# cyt4dn register map
Vendor: Cypress Semiconductor; Series: cyt4dn; File version: 1.0
CPU: CM7 r0p1, little endian, MPU, FPU, VTOR, 3 interrupt priority bits
Registers are 32-bit, read-write, reset 0x0 unless marked. A register's access mark holds for its fields unless they carry their own. Offsets are from the block's base; [hi:lo] are bit positions; lines under a group give offsets from that group; {n}, {i} and the like mark numbered series; 'fields as' and 'values as' point back to an identical list.

## VIDEOSS0 (part 13 of 18) — Video and Graphics Subsystem IP
Base 0x40A00000
0x80000 VIDEOIO group — Video I/O Core
  0x24000 DISENG1 group — Display Engine
    0x1000 SIG1 group — Signature Unit
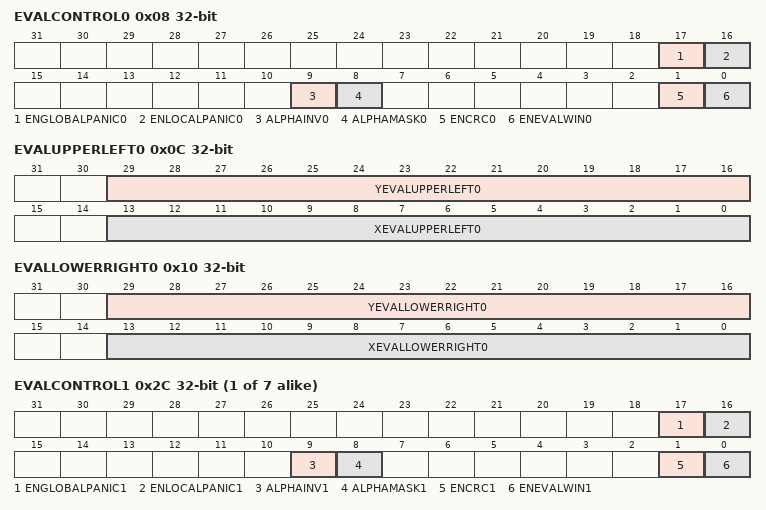
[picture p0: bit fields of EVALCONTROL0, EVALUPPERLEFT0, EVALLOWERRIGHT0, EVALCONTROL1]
      0x08 EVALCONTROL0 — Control settings for evaluation window 0.
        [17] ENGLOBALPANIC0 — When enabled (value 1) the error status of this window (StsSigError) will activate the panic mode of the display stream's Frame Generator, which can switch to another display mode in response.
        [16] ENLOCALPANIC0 — When enabled (value 1) the error status this window (StsSigError) will replace all pixels inside the window by a constant color on the display. Skip regions due to other evaluation windows on top are not modified. AlphaMask, when enabled, is not considered for this replacement.
        [9] ALPHAINV0 — When enabled (value 1) the effect of AlphaMask is inverted (pixels with alpha bit = 1 are ignored then).
        [8] ALPHAMASK0 — When enabled (value 1) pixels with alpha bit = 0 are ignored for signature computation.
        [1] ENCRC0 — When enabled (value 1) the measured signature is checked against a reference value (SigCRCRef).
        [0] ENEVALWIN0 — When enabled (value 1) a CRC signature is computed for all pixels inside this evaluation window (SigCRC). When this bit is cleared, the internal status for this window is reset (StsSigError bit and frame counters).
      0x0C EVALUPPERLEFT0 — Upper left corner of evaluation window 0.
        [29:16] YEVALUPPERLEFT0 — Y coordinate.
        [13:0] XEVALUPPERLEFT0 — X coordinate.
      0x10 EVALLOWERRIGHT0 — Lower right corner of evaluation window 0.
        [29:16] YEVALLOWERRIGHT0 — Y coordinate.
        [13:0] XEVALLOWERRIGHT0 — X coordinate.
      0x14 SIGCRCREDREF0 reset 0xFFFFFFFF — Reference signature of red channel for evaluation window 0.
        [31:0] SIGCRCREDREF0 — Reference value that is compared against measured SigCRCRed value.
      0x18 SIGCRCGREENREF0 reset 0xFFFFFFFF — Reference signature of green channel for evaluation window 0.
        [31:0] SIGCRCGREENREF0 — Reference value that is compared against measured SigCRCGreen value.
      0x1C SIGCRCBLUEREF0 reset 0xFFFFFFFF — Reference signature of blue channel for evaluation window 0.
        [31:0] SIGCRCBLUEREF0 — Reference value that is compared against measured SigCRCBlue value.
      0x20 SIGCRCRED0 ro reset 0xFFFFFFFF — Measured signature of red channel for evaluation window 0.
        [31:0] SIGCRCRED0 — CRC values from red channel.
      0x24 SIGCRCGREEN0 ro reset 0xFFFFFFFF — Measured signature of green channel for evaluation window 0.
        [31:0] SIGCRCGREEN0 — CRC values from green channel.
      0x28 SIGCRCBLUE0 ro reset 0xFFFFFFFF — Measured signature of blue channel for evaluation window 0.
        [31:0] SIGCRCBLUE0 — CRC values from blue channel.
      {0x8+0x24*l} EVALCONTROL{l} (l=1..7) — Control settings for evaluation window {l}.
        [17] ENGLOBALPANIC{l} — See EnGlobalPanic0.
        [16] ENLOCALPANIC{l} — See EnLocalPanic0.
        [9] ALPHAINV{l} — See AlphaInv0.
        [8] ALPHAMASK{l} — See AlphaMask0.
        [1] ENCRC{l} — See EnCRC0.
        [0] ENEVALWIN{l} — See EnEvalWin0.
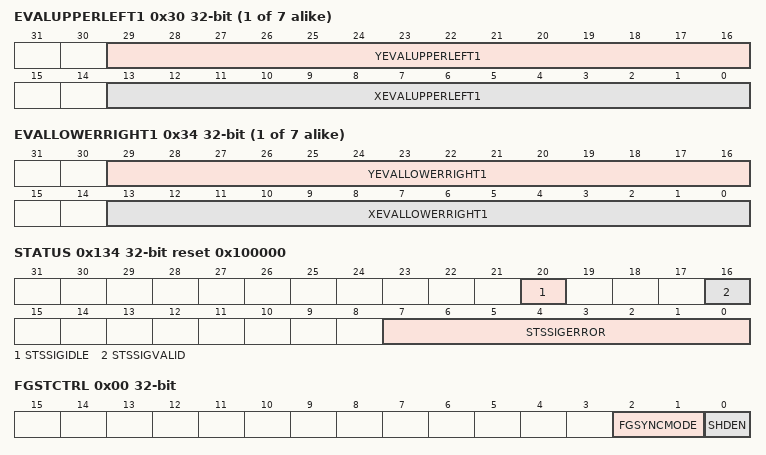
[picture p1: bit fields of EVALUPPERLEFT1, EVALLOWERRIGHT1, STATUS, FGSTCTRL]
      {0xC+0x24*l} EVALUPPERLEFT{l} (l=1..7) — Upper left corner of evaluation window {l}.
        [29:16] YEVALUPPERLEFT{l} — See YEvalUpperLeft0.
        [13:0] XEVALUPPERLEFT{l} — See XEvalUpperLeft0.
      {0x10+0x24*l} EVALLOWERRIGHT{l} (l=1..7) — Lower right corner of evaluation window {l}.
        [29:16] YEVALLOWERRIGHT{l} — See YEvalLowerRight0.
        [13:0] XEVALLOWERRIGHT{l} — See XEvalLowerRight0.
      {0x14+0x24*l} SIGCRCREDREF{l} reset 0xFFFFFFFF (l=1..7) — Reference signature of red channel for evaluation window {l}.
        [31:0] SIGCRCREDREF{l} — See SigCRCRedRef0.
      {0x18+0x24*l} SIGCRCGREENREF{l} reset 0xFFFFFFFF (l=1..7) — Reference signature of green channel for evaluation window {l}.
        [31:0] SIGCRCGREENREF{l} — See SigCRCGreenRef0.
      {0x1C+0x24*l} SIGCRCBLUEREF{l} reset 0xFFFFFFFF (l=1..7) — Reference signature of blue channel for evaluation window {l}.
        [31:0] SIGCRCBLUEREF{l} — See SigCRCBlueRef0.
      {0x20+0x24*l} SIGCRCRED{l} ro reset 0xFFFFFFFF (l=1..7) — Measured signature of red channel for evaluation window {l}.
        [31:0] SIGCRCRED{l} — See SigCRCRed0.
      {0x24+0x24*l} SIGCRCGREEN{l} ro reset 0xFFFFFFFF (l=1..7) — Measured signature of green channel for evaluation window {l}.
        [31:0] SIGCRCGREEN{l} — See SigCRCGreen0.
      {0x28+0x24*l} SIGCRCBLUE{l} ro reset 0xFFFFFFFF (l=1..7) — Measured signature of blue channel for evaluation window {l}.
        [31:0] SIGCRCBLUE{l} — See SigCRCBlue0.
      0x128 SHADOWLOAD — Shadow load control register.
        [7:0] SHDLDREQ — Shadow load request for each evaluation window (bit index = window index). Writing a '1' to a bit will load the shadows into the active configuration for that window at start of next frame. Writing a '0' has no effect. The flag is reset by HW once the shadows have been loaded. A shadow load interrupt signal is generated when shadows have been loaded for at least one evaluation window. Has only effect when ShdLdSel is set to LOCAL.
      0x12C CONTINUOUSMODE — Signature operation mode control.
        [0] ENCONT — EnCont = 0: disables continuous mode. Signatures will be generated only once and in idle state after completion of measurement. In this 'ONE_TIME' mode the signature must be triggered by 'Kick' field. EnCont = 1: enables continuous mode. Write '1' to this field, signature starts and measures every incoming frame until EnCont is turned to 0. 'Kick' has no effect when 'EnCont' = 1.
      0x130 SOFTWAREKICK wo reset not defined — Signature measurement trigger.
        [0] KICK — ContinueMode.EnCont=0: Write '1' to this field in order to start signature computation with next frame. ContinueMode.EnCont=1: This field is ignored.
      0x134 STATUS ro reset 0x100000 — Module status.
        [20] STSSIGIDLE — StsSigIdle = 1: Signature is in Idle state. StsSigIdle = 0: Signature runs.
        [16] STSSIGVALID — Measured signature values are valid. This flag is set when the SigCRC fields have been updated for all enabled evaluation windows. In that case also the corresponding interrupt event is triggered. It is reset when SW writes a '1' to the 'Kick' field in order to start a new measurement.
        [7:0] STSSIGERROR — Error status bits for all evaluation windows (bit index = window index). When a bit is set it means that measured signature value is different from reference value (SigCRCRef). The bit is set when EnCRC is active and a certain number of frames have a violation (ErrThres). It is reset when the reference check for evaluation window is disabled (EnEvalWin or EnCRC) or in case a certain number of consecutive frames have no violation (ErrThresReset). The value corresponds to the panic status of this evaluation window.
    0x2000 FRAMEGEN1 group — Frame Generator
      0x00 FGSTCTRL — FrameGen Static Control Register
        [2:1] FGSYNCMODE — Determines the operating mode of the framegen unit for side-by-side synchronization. The framegen unit programmed as master generates synchronization pulses. The framegen units programmed as slaves are synchronized to the master unit. There must be only one framegen unit programmed acting as master.
          0=OFF (No side-by-side synchronization.); 1=MASTER (Framegen is master.); 2=SLAVE_CYC (Framegen is slave. Runs in cyclic synchronization mode.); 3=SLAVE_ONCE (Framegen is slave. Runs in one time synchronization mode.)
        [0] SHDEN — Enables shadowing for RWS type configuration fields. Otherwise shadow registers are immediately updated when written.
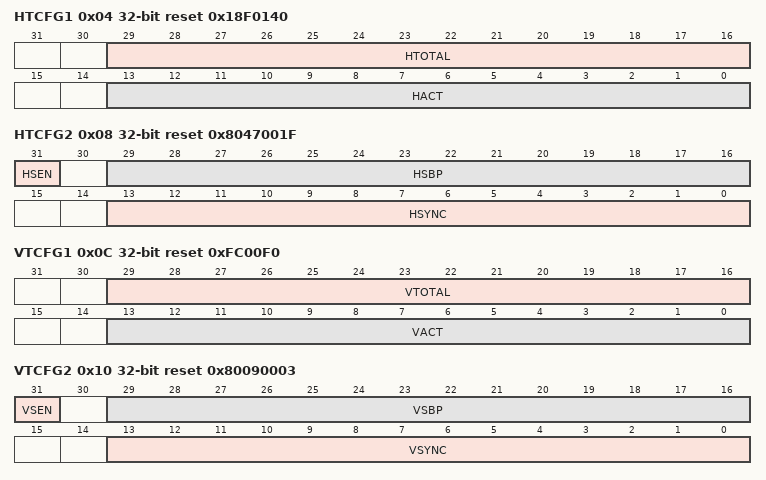
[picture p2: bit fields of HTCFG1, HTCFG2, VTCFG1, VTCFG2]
      0x04 HTCFG1 reset 0x18F0140 — FrameGen Horizontal Timing Config Register 1
        [29:16] HTOTAL — Total horizontal size of frame in pixels. (Set value +1 is the total horizontal size of frame) Htotal shall be greater or equal than Hact + Hsbp. Note1: Valid setup for horizontal video timing contains parameters Hact, Htotal, Hsbp and, if enabled, Hsync. Note2: If SRAdj==1 then Htotal[0] shall be equal the value of SREven (for sec. channel only).
        [13:0] HACT — Horizontal size of active display area in pixels. Hact shall be greater or equal than 4. Note: Valid setup for horizontal video timing contains parameters Hact, Htotal, Hsbp and, if enabled, Hsync.
      0x08 HTCFG2 reset 0x8047001F — FrameGen Horizontal Timing Config Register 2
        [31] HSEN — Enables generation of HSYNC pulse.
        [29:16] HSBP — Width of HSYNC pulse plus width of horizontal back porch in pixels. (Set value +1 is the width of HSYNC pulse plus width of horizontal back porch) Hsbp shall be greater or equal than Hsync. Note: Valid setup for horizontal video timing contains parameters Hact, Htotal, Hsbp and, if enabled, Hsync.
        [13:0] HSYNC — Width of HSYNC pulse in pixels. (Set value +1 is the width of HSYNC pulse) HSYNC is of zero width if HsEn==0. Note: Valid setup for horizontal video timing contains parameters Hact, Htotal, Hsbp and, if enabled, Hsync.
      0x0C VTCFG1 reset 0xFC00F0 — FrameGen Vertical Timing Config Register 1
        [29:16] VTOTAL — Total vertical size of frame in lines. (Set value +1 is the total vertical size of frame) Vtotal shall be greater or equal than Vact + Vsbp. Note: Valid setup for vertical video timing contains parameters Vact, Vtotal, Vsbp and, if enabled, Vsync.
        [13:0] VACT — Vertical size of active display area in lines. Vact shall be greater or equal than 4. Note: Valid setup for vertical video timing contains parameters Vact, Vtotal, Vsbp and, if enabled, Vsync.
      0x10 VTCFG2 reset 0x80090003 — FrameGen Vertical Timing Config Register 2
        [31] VSEN — Enables generation of VSYNC pulse.
        [29:16] VSBP — Width of VSYNC pulse plus width of vertical back porch in lines. (Set value +1 is the width of VSYNC pulse plus width of vertical back porch) Vsbp shall be greater or equal than Vsync. Note: Valid setup for vertical video timing contains parameters Vact, Vtotal, Vsbp and, if enabled, Vsync.
        [13:0] VSYNC — Width of VSYNC pulse in lines. (Set value +1 is the width of VSYNC pulse) VSYNC is of zero width if VsEn==0. Note: Valid setup for vertical video timing contains parameters Vact, Vtotal, Vsbp and, if enabled, Vsync.
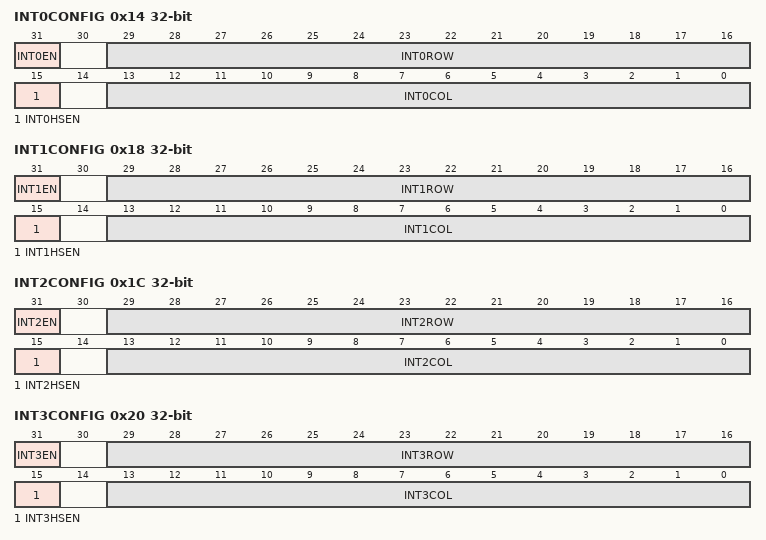
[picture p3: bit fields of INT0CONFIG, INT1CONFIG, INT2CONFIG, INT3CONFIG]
      0x14 INT0CONFIG — Coordinates of the trigger point for generation of the Int0 interrupt signal
        [31] INT0EN — Enables Int0.
        [29:16] INT0ROW — Specifies on which row of the display raster the Int0 signal is triggered (1 .. Int0Row .. VTOTAL). Adaptive display timing must be taken into account when defining Int0Row (1 .. Int0Row .. VTOTAL_MIN).
        [15] INT0HSEN — When enabled, Int0Row setting is ignored so that the interrupt occurs every line at position given by Int0Col.
        [13:0] INT0COL — Specifies on which column of the display raster the Int0 signal is triggered (1 .. Int0Col .. HTOTAL). Adaptive display timing must be taken into account when defining Int0Col (1 .. Int0Col .. HTOTAL_MIN).
      0x18 INT1CONFIG — Coordinates of the trigger point for generation of the Int1 interrupt signal
        [31] INT1EN — Enables Int1 (irq[1]).
        [29:16] INT1ROW — Specifies on which row of the display raster the Int1 signal is triggered (1 .. Int1Row .. VTOTAL). Adaptive display timing must be taken into account when defining Int1Row (1 .. Int1Row .. VTOTAL_MIN).
        [15] INT1HSEN — When enabled, Int1Row setting is ignored so that the interrupt occurs every line at position given by Int1Col.
        [13:0] INT1COL — Specifies on which column of the display raster the Int1 signal is triggered (1 .. Int1Col .. HTOTAL). Adaptive display timing must be taken into account when defining Int1Col (1 .. Int1Col .. HTOTAL_MIN).
      0x1C INT2CONFIG — Coordinates of the trigger point for generation of the Int2 interrupt signal
        [31] INT2EN — Enables Int2.
        [29:16] INT2ROW — Specifies on which row of the display raster the Int2 signal is triggered (1 .. Int2Row .. VTOTAL). Adaptive display timing must be taken into account when defining Int2Row (1 .. Int2Row .. VTOTAL_MIN).
        [15] INT2HSEN — When enabled, Int2Row setting is ignored so that the interrupt occurs every line at position given by Int2Col.
        [13:0] INT2COL — Specifies on which column of the display raster the Int2 signal is triggered (1 .. Int2Col .. HTOTAL). Adaptive display timing must be taken into account when defining Int2Col (1 .. Int2Col .. HTOTAL_MIN).
      0x20 INT3CONFIG — Coordinates of the trigger point for generation of the Int3 interrupt signal
        [31] INT3EN — Enables Int3.
        [29:16] INT3ROW — Specifies on which row of the display raster the Int3 signal is triggered (1 .. Int3Row .. VTOTAL). Adaptive display timing must be taken into account when defining Int3Row (1 .. Int3Row .. VTOTAL_MIN).
        [15] INT3HSEN — When enabled, Int3Row setting is ignored so that the interrupt occurs every line at position given by Int3Col.
        [13:0] INT3COL — Specifies on which column of the display raster the Int3 signal is triggered (1 .. Int3Col .. HTOTAL). Adaptive display timing must be taken into account when defining Int3Col (1 .. Int3Col .. HTOTAL_MIN).
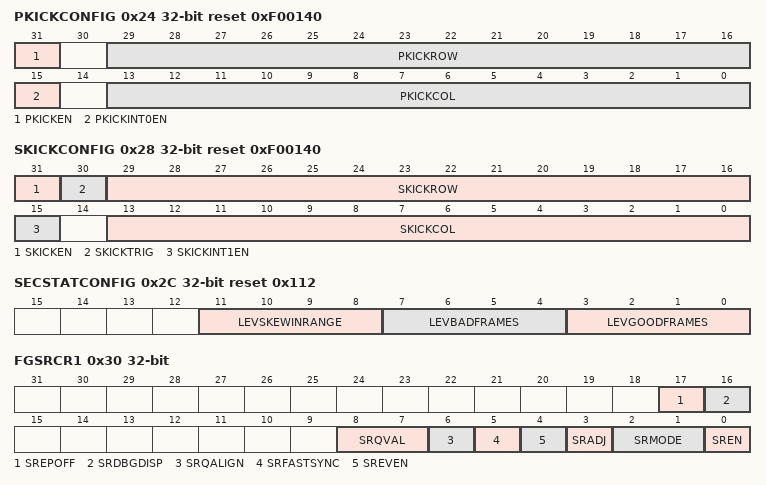
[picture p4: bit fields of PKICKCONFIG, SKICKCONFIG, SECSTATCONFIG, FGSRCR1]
      0x24 PKICKCONFIG reset 0xF00140 — Coordinates of the trigger point for generation of the primary kick signal
        [31] PKICKEN — Enables pkick signal.
        [29:16] PKICKROW — Specifies on which row of the display raster the pkick signal is triggered (1 .. PKickRow .. VTOTAL). Adaptive display timing must be taken into account when defining PKickRow (1 .. PKickRow .. VTOTAL_MIN).
        [15] PKICKINT0EN — If enabled, maps the primary kick signal (pkick) on the interrupt pin int0. Overrides int0en.
        [13:0] PKICKCOL — Specifies on which column of the display raster the pkick signal is triggered (1 .. PKickCol .. HTOTAL). Adaptive display timing must be taken into account when defining PKickCol (1 .. PKickCol .. HTOTAL_MIN).
      0x28 SKICKCONFIG reset 0xF00140 — Coordinates of the trigger point for generation of the secondary kick signal
        [31] SKICKEN — Enables generation of internal skick signal.
        [30] SKICKTRIG — Select source for skick generation.
          0=INTERNAL (Use internal skick signal, trigger point defined by SKickRow and SKickCol.); 1=EXTERNAL (Use external skick input as trigger.)
        [29:16] SKICKROW — Specifies on which row of the display raster the skick signal is triggered (1 .. SKickRow .. VTOTAL). Adaptive display timing must be taken into account when defining SKickRow (1 .. SKickRow .. VTOTAL_MIN).
        [15] SKICKINT1EN — If enabled, maps the secondary kick signal (skick) on the interrupt pin int1. Overrides int1en.
        [13:0] SKICKCOL — Specifies on which column of the display raster the skick signal is triggered (1 .. SKickCol .. HTOTAL). Adaptive display timing must be taken into account when defining SKickCol (1 .. SKickCol .. HTOTAL_MIN).
      0x2C SECSTATCONFIG reset 0x112 — Configuration register for controlling the behavior of the SecSyncStat field in the FgSecChStat register.
        [11:8] LEVSKEWINRANGE — Number of continuous frames the measured skew value shall be within the range defined by SyncRangeLow and SyncRangeHigh. If this condition is true, additionally LevGoodFrames valid frames must be processed before the status line of the sec. channel and the SecSyncStat status field goes to 1 indicating synchronized status. Value of 0 is not allowed.
        [7:4] LEVBADFRAMES — Not used.
        [3:0] LEVGOODFRAMES — Number of continuous correct frames that must be processed before SecSyncStat field goes 1 (in sync). Value of 0 is not allowed.
      0x30 FGSRCR1 — FrameGen Skew Regulation Control Register 1.
        [17] SREPOFF — Disables the skew Extrapolation in blanking.
        [16] SRDBGDISP — If enabled, the pixels are displayed that are read from FIFO when secondary channel is not in sync yet. Otherwise constant color is displayed in unsynchronized state.
        [8:7] SRQVAL — If SRQAlign is enabled, this field determines the fixed value of the two LSB bits of HTOTAL. Note: This has impact on the settings for Htotal, HtotalMin and HtotalMax.
          0=ZERO (Fixed two LSB values of HTOTAL are 0b00.); 1=ONE (Fixed two LSB values of HTOTAL are 0b01.); 2=TWO (Fixed two LSB values of HTOTAL are 0b10.); 3=THREE (Fixed two LSB values of HTOTAL are 0b11.)
        [6] SRQALIGN — Enables alignment of HTOTAL to be a multiple of 4. Overrides SREven field. Program field SRQVal for the desired value of the two LSB bits of HTOTAL.
        [5] SRFASTSYNC — Fast Synchronization Mode. Frame Generator is started synchronized to frame timing on secondary channel when switching FgEn from 0 to 1. This allows fast locking of skew regulation.
        [4] SREVEN — Total line length HTOTAL is even when SRAdj is enabled. Note: This has impact on the settings for Htotal, HtotalMin and HtotalMax.
        [3] SRADJ — Enables line length adjustment for HTOTAL. If SRQAlign=0, SREven determines whether HTOTAL has odd (SREven=0) or even (SrEven=1) number of pixels. If SRQAlign=1, SRQVal determines the value of the two LSB bits of HTOTAL.
        [2:1] SRMODE — Skew Control Operating Mode.
          0=OFF (Skew Regulation is off.); 1=HREG (Horizontal regulation enabled.); 2=VREG (Vertical regulation enabled.); 3=BOTH (Both regulation modes are enabled.)
        [0] SREN — If enabled, skew control for secondary channel is active. If disabled, skew control for secondary channel is in fetch mode. Fetch mode: secondary channel fetches frames and can intentionally produce a backstall via setting sbusy signal to active. This mode is intended to fetch frames from memory via a stallable pipeline, like the primary interface. No timing adaption of frames takes place in this mode.
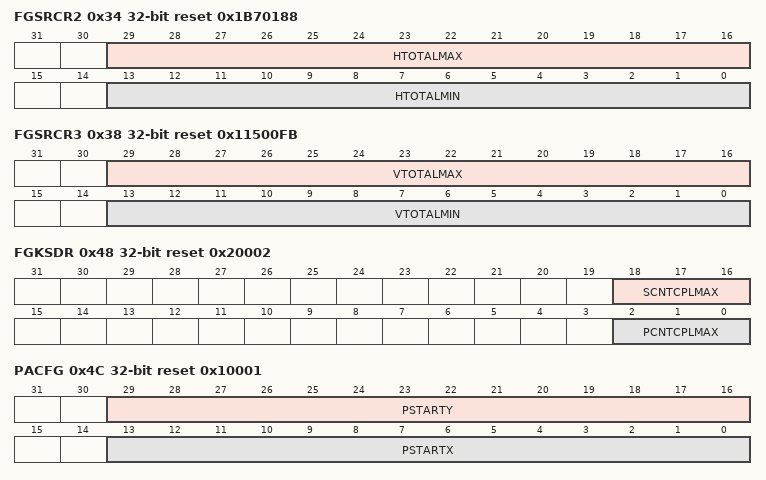
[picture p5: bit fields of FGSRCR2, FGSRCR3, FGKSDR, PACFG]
      0x34 FGSRCR2 reset 0x1B70188 — FrameGen Skew Regulation Control Register 2
        [29:16] HTOTALMAX — Maximum value of htotal when horizontal regulation is enabled. (Set value +1 is the maximum value of htotal) HTotalMax must be greater or equal Htotal. Note: If SRAdj==1 then HtotalMax[0] shall be equal to the value of SREven.
        [13:0] HTOTALMIN — Minimum value of htotal when horizontal regulation is enabled. (Set value +1 is the minimum value of htotal, must be greater or equal Hsbp + Hactive) HTotalMin must be smaller or equal Htotal. Note: If SRAdj==1 then HtotalMin[0] shall be equal to the value of SREven.
      0x38 FGSRCR3 reset 0x11500FB — FrameGen Skew Regulation Control Register 3
        [29:16] VTOTALMAX — Maximum value of vtotal when vertical regulation is enabled. (Set value +1 is the maximum value of vtotal)
        [13:0] VTOTALMIN — Minimum value of vtotal when vertical regulation is enabled. (Set value +1 is the minimum value of vtotal, must be greater or equal Vsbp + Vactive + 1)
      0x3C FGSRCR4 reset 0xC8 — FrameGen Skew Regulation Control Register 4
        [28:0] TARGETSKEW — Horizontal target skew value for horizontal and vertical skew regulation (signed value). (format is signed integer)
      0x40 FGSRCR5 — FrameGen Skew Regulation Control Register 5
        [28:0] SYNCRANGELOW — Sync range of horizontal and vertical skew regulation. Lower value (signed value). If skew stays within programmed sync range, frame status is assumed synchronized. (format is signed integer)
      0x44 FGSRCR6 reset 0x190 — FrameGen Skew Regulation Control Register 6
        [28:0] SYNCRANGEHIGH — Sync range of horizontal and vertical skew regulation. Upper value (signed value). If skew stays within programmed sync range, frame status is assumed synchronized. (format is signed integer)
      0x48 FGKSDR reset 0x20002 — FrameGen Kick System Debug Register
        [18:16] SCNTCPLMAX — Maximum Value for spendcnt_cpl_s complementary secondary kick counter. Do not change!
        [2:0] PCNTCPLMAX — Maximum Value for ppendcnt_cpl_s complementary primary kick counter. Do not change!
      0x4C PACFG reset 0x10001 — FrameGen Primary Area Config Register 1 (shadowed)
        [29:16] PSTARTY — Primary screen upper left corner, y component. Counts from 1. Pstarty = 0 is not allowed. Primary screen shall not overlap the last column/ last row of the total frame defined by Htotal/ Vtotal.
        [13:0] PSTARTX — Primary screen upper left corner, x component. Counts from 1. Pstartx = 0 is not allowed. Primary screen shall not overlap the last column/ last row of the total frame defined by Htotal/ Vtotal.
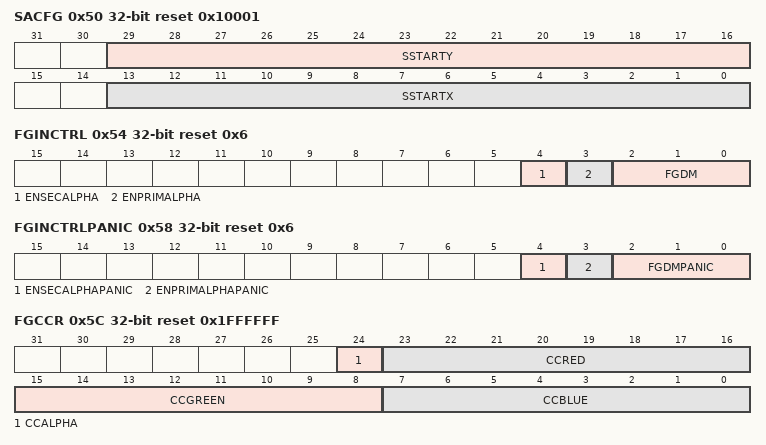
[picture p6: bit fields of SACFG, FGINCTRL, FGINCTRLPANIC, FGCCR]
      0x50 SACFG reset 0x10001 — FrameGen Secondary Area Config Register 1 (shadowed)
        [29:16] SSTARTY — Secondary screen upper left corner, y component. Counts from 1 . Sstarty = 0 is not allowed. Secondary screen shall not overlap the last column/ last row of the total frame defined by Htotal/ Vtotal. When skew regulation feature is enabled, the secondary screen shall not overlap the active display area defined by Hact and Vact.
        [13:0] SSTARTX — Secondary screen upper left corner, x component. Counts from 1 . Sstartx = 0 is not allowed. Secondary screen shall not overlap the last column/ last row of the total frame defined by Htotal/ Vtotal. When skew regulation feature is enabled, the secondary screen shall not overlap the active display area defined by Hact and Vact.
      0x54 FGINCTRL reset 0x6 — FrameGen Input Control Register (shadowed)
        [4] ENSECALPHA — When enabled, alpha plane of secondary channel is considered for screen composition. If the alpha component of the current pixel is 255, this pixel is opaque. Otherwise this pixel is transparent. Setting this field to 1 has no effect, when FgDm == BLEND.
        [3] ENPRIMALPHA — When enabled, alpha plane of primary channel is considered for screen composition. If the alpha component of the current pixel is 255, this pixel is opaque. Otherwise this pixel is transparent. Setting this field to 1 has no effect, when FgDm == BLEND.
        [2:0] FGDM — Frame Generator Display Mode.
          0=BLACK (Black color background is shown on the whole screen area.); 1=CONSTCOL (Programmable constant color is shown in the active area and black color in the blanking area.); 2=PRIM (Primary input only is shown.); 3=SEC (Secondary input only is shown.); 4=PRIM_ON_TOP (Both inputs overlaid with primary on top.); 5=SEC_ON_TOP (Both inputs overlaid with secondary on top.); 6=TEST (White color background with test pattern is shown in the active area and black color in the blanking area.); 7=BLEND (Blending of the mode PRIM with the mode SEC.)
      0x58 FGINCTRLPANIC reset 0x6 — FrameGen Input Control Panic Register (shadowed)
        [4] ENSECALPHAPANIC — When enabled, alpha plane of secondary channel is considered for screen composition. If the alpha component of the current pixel is 255, this pixel is opaque. Otherwise this pixel is transparent. Setting this field to 1 has no effect, when FgDmPanic == BLEND.
        [3] ENPRIMALPHAPANIC — When enabled, alpha plane of primary channel is considered for screen composition. If the alpha component of the current pixel is 255, this pixel is opaque. Otherwise this pixel is transparent. Setting this field to 1 has no effect, when FgDmPanic == BLEND.
        [2:0] FGDMPANIC — Frame Generator Display Mode.
          values as VIDEOIO.DISENG1.FRAMEGEN1.FGINCTRL.FGDM
      0x5C FGCCR reset 0x1FFFFFF — FrameGen Constant Color Register (shadowed)
        [24] CCALPHA — Constant color - alpha value. In case of blending the value of 1 will be extended to 0xff.
        [23:16] CCRED — Constant color - red component.
        [15:8] CCGREEN — Constant color - green component.
        [7:0] CCBLUE — Constant color - blue component.
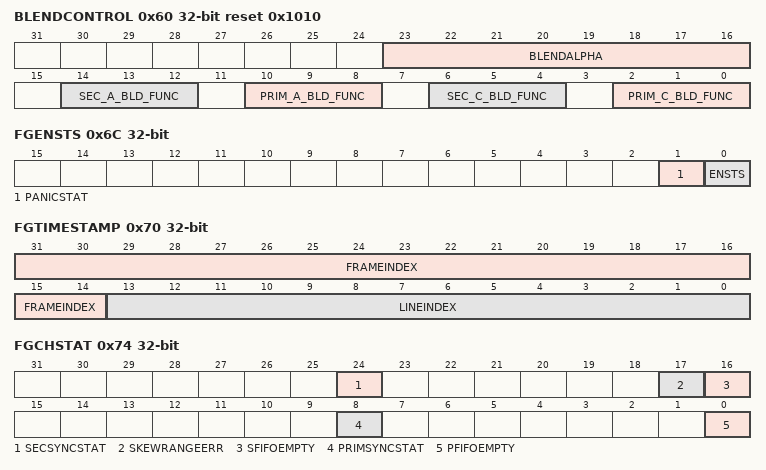
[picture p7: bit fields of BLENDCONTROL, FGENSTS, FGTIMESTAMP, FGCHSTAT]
      0x60 BLENDCONTROL reset 0x1010 — Options for blend operations. (shadowed)
        [23:16] BLENDALPHA — Constant alpha value, used for constant alpha blending
        [14:12] SEC_A_BLD_FUNC — Secondary (overlay) input alpha blending function
          0=ZERO (Aout = Ain * 0); 1=ONE (Aout = Ain * 1); 2=PRIM_ALPHA (Aout = Ain * ALPHA_prim); 3=ONE_MINUS_PRIM_ALPHA (Aout = Ain * (1 - ALPHA_prim)); 4=SEC_ALPHA (Aout = Ain * ALPHA_sec); 5=ONE_MINUS_SEC_ALPHA (Aout = Ain * (1 - ALPHA_sec)); 6=CONST_ALPHA (Aout = Ain * ALPHA_const); 7=ONE_MINUS_CONST_ALPHA (Aout = Ain * (1 - ALPHA_const))
        [10:8] PRIM_A_BLD_FUNC — Primary (background) input alpha blending function
          values as SEC_A_BLD_FUNC
        [6:4] SEC_C_BLD_FUNC — Secondary (overlay) input color blending function
          0=ZERO (Cout = Cin * 0); 1=ONE (Cout = Cin * 1); 2=PRIM_ALPHA (Cout = Cin * ALPHA_prim); 3=ONE_MINUS_PRIM_ALPHA (Cout = Cin * (1 - ALPHA_prim)); 4=SEC_ALPHA (Cout = Cin * ALPHA_sec); 5=ONE_MINUS_SEC_ALPHA (Cout = Cin * (1 - ALPHA_sec)); 6=CONST_ALPHA (Cout = Cin * ALPHA_const); 7=ONE_MINUS_CONST_ALPHA (Cout = Cin * (1 - ALPHA_const))
        [2:0] PRIM_C_BLD_FUNC — Primary (background) input color blending function
          values as SEC_C_BLD_FUNC
      0x64 FGENABLE — FrameGen Enable Register
        [0] FGEN — Frame Generator Enable. Note: For loading the shadow registers at start-up of FrameGen unit write the FgSlr.ShdTokGen field immediately before writing this field.
      0x68 FGSLR wo reset not defined — FrameGen Shadow Load Register
        [0] SHDTOKGEN — Generate shadow load token. Can be used to load shadow register in this and/or all subsequent units up to the next token end point.
      0x6C FGENSTS ro — FrameGen Enable Status Register
        [1] PANICSTAT — Current status of panic mode (0=normal operation mode, 1=panic mode; not locked).
        [0] ENSTS — Indicates the current operating mode of the frame generator. EnSts = 0 means frame generator is disabled. EnSts = 1 means frame generator is enabled. In contrast to the FgEn field of the FgEnable register this bit goes only 0 when all pending frames are processed.
      0x70 FGTIMESTAMP ro — Time stamp status.
        [31:14] FRAMEINDEX — Index of the output frame that is currently generated (starts with 0 after reset for first output frame). Wraps around to 0 when maximum value is reached.
        [13:0] LINEINDEX — Index of the output line that is currently generated (starts with 0 for first active output line).
      0x74 FGCHSTAT ro — FrameGen Channel Status Register
        [24] SECSYNCSTAT — Current status secondary channel synchronization (0 = out of sync, 1 = in sync; not locked).
        [17] SKEWRANGEERR — The secondary channel skew value has run out of the limit defined by SyncRangeLow and SyncRangeHigh. (bit locked when 1, clear by using ClrSecStat).
        [16] SFIFOEMPTY — Read request to empty secondary pixel FIFO detected. (bit locked when 1, clear by using ClrSecStat).
        [8] PRIMSYNCSTAT — Current status primary channel synchronization (0 = out of sync (frame tearing), 1 = in sync (normal operation); not locked).
        [0] PFIFOEMPTY — Read request to empty primary pixel FIFO detected. (Bit locked when 1, clear by using ClrPrimStat).
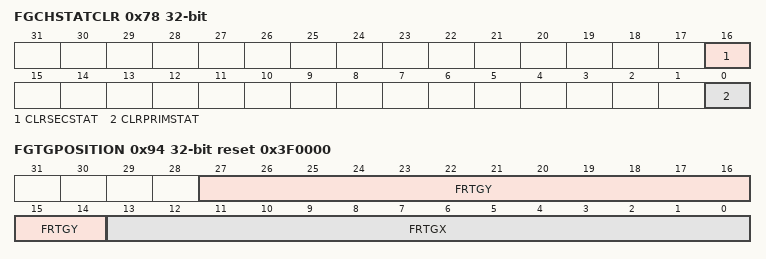
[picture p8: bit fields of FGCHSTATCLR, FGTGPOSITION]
      0x78 FGCHSTATCLR wo reset not defined — FrameGen Channel Status Clear Register
        [16] CLRSECSTAT — Clears SFifoEmpty and SkewRangeErr in FgChStat register.
        [0] CLRPRIMSTAT — Clears PFifoEmpty in FgChStat register.
      0x7C FGSKEWMON ro — FrameGen Skew Monitor Register for Secondary Channel Skew Control
        [28:0] SKEWMON — Current skew value monitor for secondary channel skew control. Updated with hlast. (For debugging purposes only).
      0x80 FGSFIFOMIN ro reset not defined — FrameGen Secondary FIFO Min Fill Register
        [10:0] SFIFOMIN — Shows the minimal fill level of the secondary channel pixel FIFO. (For debugging purposes only).
      0x84 FGSFIFOMAX ro reset not defined — FrameGen Secondary FIFO Max Fill Register
        [10:0] SFIFOMAX — Shows the maximal fill level of the secondary channel pixel FIFO. (For debugging purposes only).
      0x88 FGSFIFOFILLCLR wo reset not defined — FrameGen Secondary FIFO Fill Clear Register
        [0] SFIFOFILLCLR — Write for clearing register FgSFifoMin and FgSFifoMax. (For debugging purposes only).
      0x8C FGSREPD ro — FrameGen Skew Regulation ExtraPolation Debug Register
        [28:0] EPVAL — Calculated value for line skew extrapolation in blanking. Updated with condition 'hlast AND vlast'. (For debugging purposes only)
      0x90 FGSRFTD ro — FrameGen Skew Regulation Frame Total Debug Register
        [27:0] FRTOT — Measured value for frame total measured in display clock cycles. Updated with condition 'hlast AND vlast' when first FrTot value is valid. (For debugging purposes only)
      0x94 FGTGPOSITION ro reset 0x3F0000 — Current (x,y) positions of the timing generator register in FrameGen timing generator.
        [27:14] FRTGY — Coordinated line position starting from VACT inside a total frame generated in timing generator in display clock cycles. (For debugging purposes only)
        [13:0] FRTGX — Coordinated pixel position starting from HACT inside a total line generated in timing generator in display clock cycles. (For debugging purposes only)
